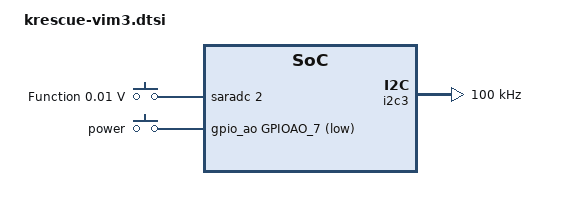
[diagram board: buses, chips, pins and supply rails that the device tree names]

// VIM3 add

&i2c3{
    pinctrl-0 = <&i2c3_sck_a_pins>, <&i2c3_sda_a_pins>;
    clock-frequency = <100000>; /* default 100k */
    pinctrl-names = "default";
    status = "okay";
};


/ {
    adc-keys {
    compatible = "adc-keys";
    io-channels = <&saradc 2>;
    io-channel-names = "buttons";
    keyup-threshold-microvolt = <1710000>;

    key_f: button-function {
        label = "Function";
        linux,code = <KEY_FN>;
        press-threshold-microvolt = <10000>;
    };
    };

    gpio-keys-polled {
    compatible = "gpio-keys-polled";
    poll-interval = <100>;

    key_p: power-button {
        label = "power";
        linux,code = <KEY_POWER>;
        gpios = <&gpio_ao GPIOAO_7 GPIO_ACTIVE_LOW>;
    };
    };
};

&led_red{
    default-state = "off";
};

&led_white{
    default-state = "on";
    linux,default-trigger = "heartbeat";
};
